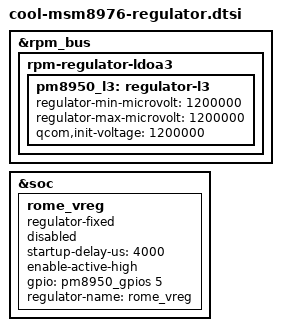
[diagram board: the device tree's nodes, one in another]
/*
 * Copyright (c) 2014-2016, The Linux Foundation. All rights reserved.
 *
 * This program is free software; you can redistribute it and/or modify
 * it under the terms of the GNU General Public License version 2 and
 * only version 2 as published by the Free Software Foundation.
 *
 * This program is distributed in the hope that it will be useful,
 * but WITHOUT ANY WARRANTY; without even the implied warranty of
 * MERCHANTABILITY or FITNESS FOR A PARTICULAR PURPOSE.  See the
 * GNU General Public License for more details.
 */

&rpm_bus {
	rpm-regulator-ldoa3 {
		pm8950_l3: regulator-l3 {
			regulator-min-microvolt = <1200000>;
			regulator-max-microvolt = <1200000>;
			qcom,init-voltage = <1200000>;
		};
	};
};

&soc {
	/* Rome 3.3V supply */
	rome_vreg: rome_vreg {
		compatible = "regulator-fixed";
		startup-delay-us = <4000>;
		enable-active-high;
		gpio = <&pm8950_gpios 5 0>;
		regulator-name = "rome_vreg";
		status = "disabled";
	};
};

